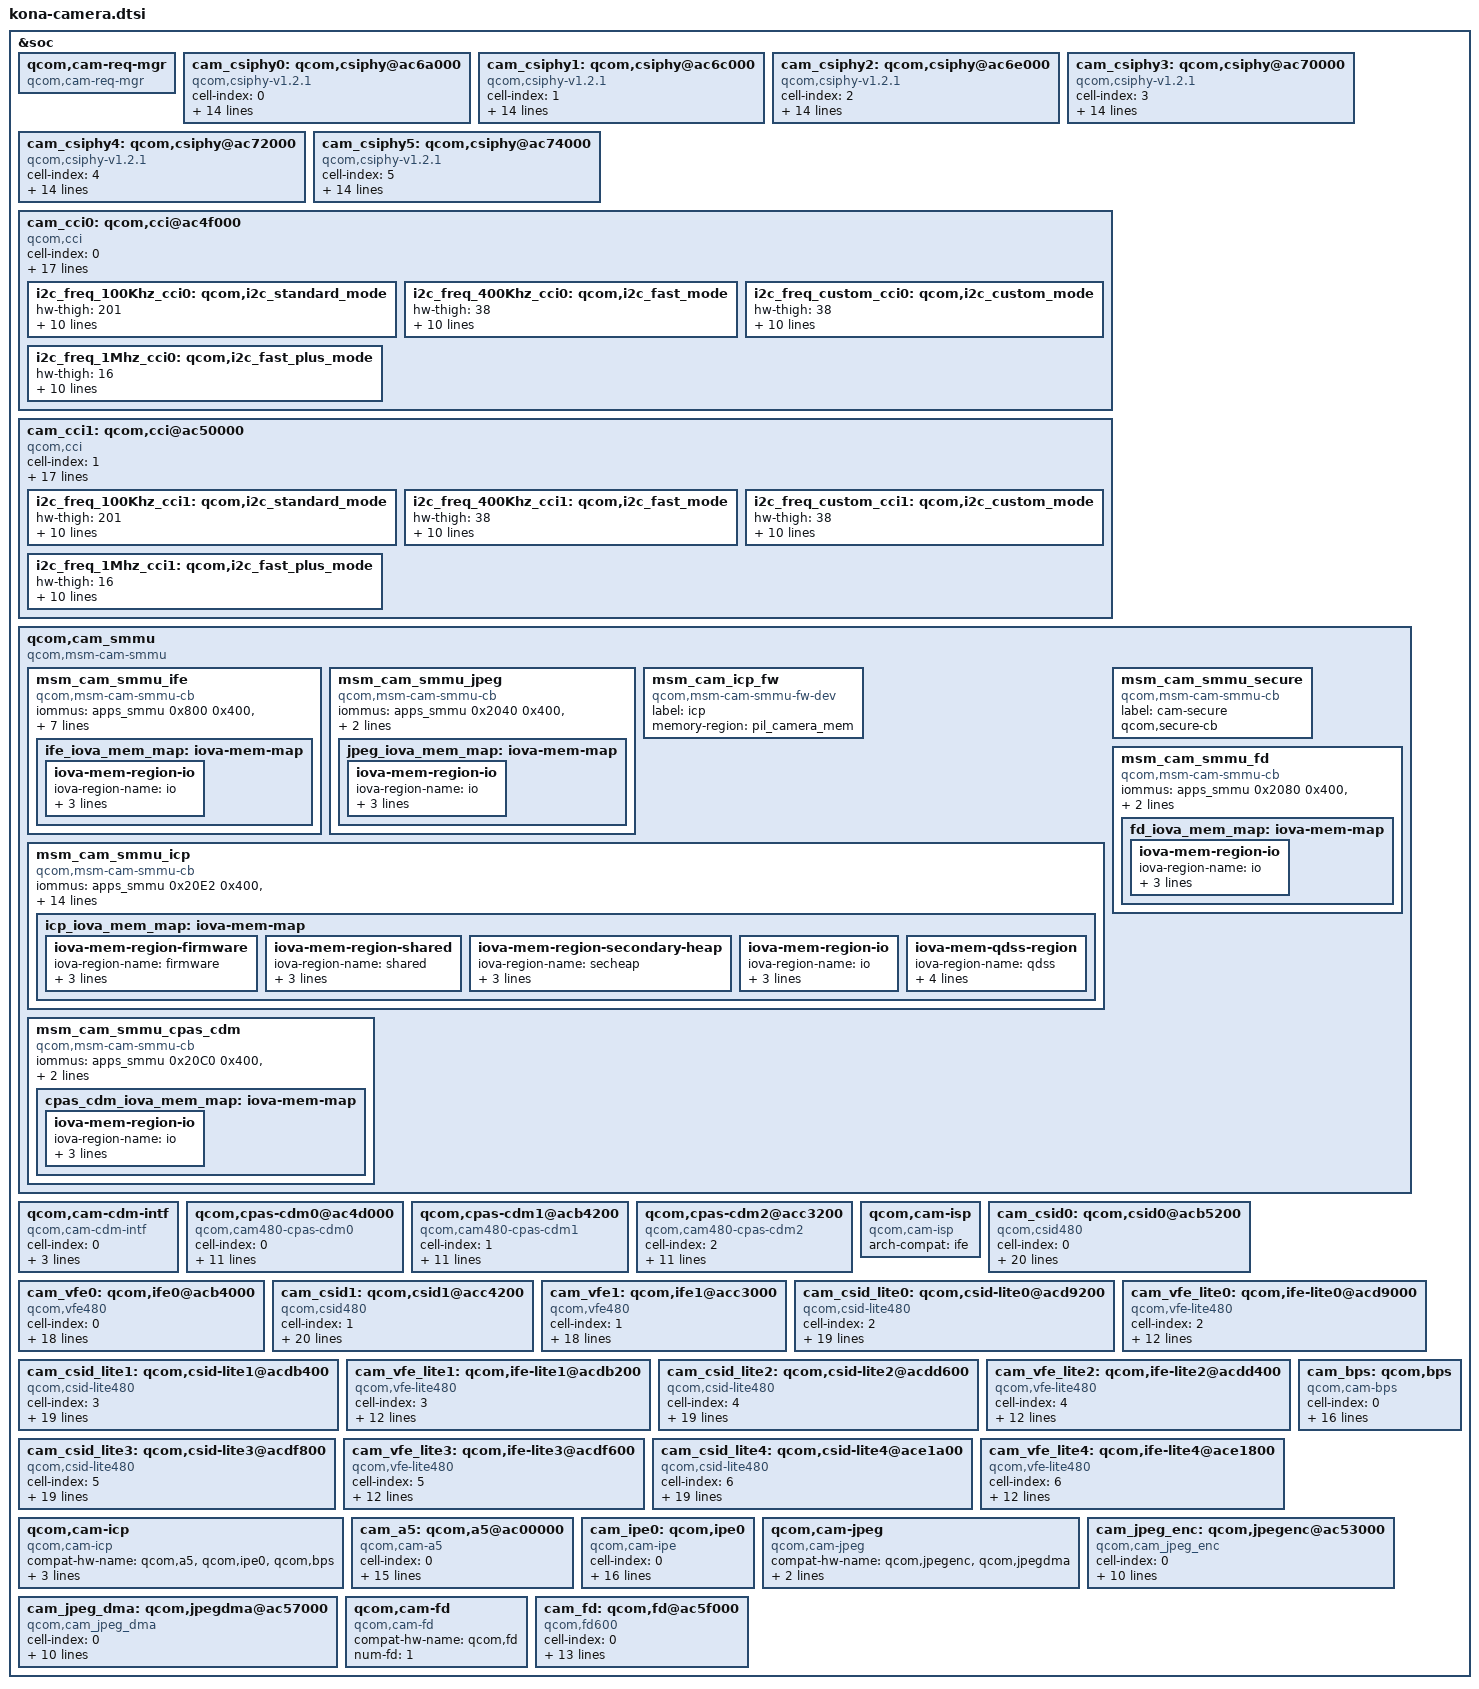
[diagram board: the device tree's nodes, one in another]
// SPDX-License-Identifier: GPL-2.0-only
/*
 * Copyright (c) 2018, The Linux Foundation. All rights reserved.
 */

&soc {
	qcom,cam-req-mgr {
		compatible = "qcom,cam-req-mgr";
		status = "ok";
	};

	cam_csiphy0: qcom,csiphy@ac6a000 {
		cell-index = <0>;
		compatible = "qcom,csiphy-v1.2.1", "qcom,csiphy";
		reg = <0x0ac6a000 0x2000>;
		reg-names = "csiphy";
		reg-cam-base = <0x6a000>;
		interrupts = <GIC_SPI 477 IRQ_TYPE_EDGE_RISING>;
		interrupt-names = "csiphy";
		gdscr-supply = <&titan_top_gdsc>;
		regulator-names = "gdscr";
		csi-vdd-voltage = <1200000>;
		mipi-csi-vdd-supply = <&pm8150_l9>;
		clocks = <&clock_camcc CAM_CC_CPHY_RX_CLK_SRC>,
			<&clock_camcc CAM_CC_CSIPHY0_CLK>,
			<&clock_camcc CAM_CC_CSI0PHYTIMER_CLK_SRC>,
			<&clock_camcc CAM_CC_CSI0PHYTIMER_CLK>;
		clock-names = "cphy_rx_clk_src",
			"csiphy0_clk",
			"csi0phytimer_clk_src",
			"csi0phytimer_clk";
		src-clock-name = "csi0phytimer_clk_src";
		clock-cntl-level = "turbo";
		clock-rates =
			<400000000 0 300000000 0>;
		status = "ok";
	};

	cam_csiphy1: qcom,csiphy@ac6c000 {
		cell-index = <1>;
		compatible = "qcom,csiphy-v1.2.1", "qcom,csiphy";
		reg = <0xac6c000 0x2000>;
		reg-names = "csiphy";
		reg-cam-base = <0x6c000>;
		interrupts = <GIC_SPI 478 IRQ_TYPE_EDGE_RISING>;
		interrupt-names = "csiphy";
		gdscr-supply = <&titan_top_gdsc>;
		regulator-names = "gdscr";
		csi-vdd-voltage = <1200000>;
		mipi-csi-vdd-supply = <&pm8150_l9>;
		clocks = <&clock_camcc CAM_CC_CPHY_RX_CLK_SRC>,
			<&clock_camcc CAM_CC_CSIPHY1_CLK>,
			<&clock_camcc CAM_CC_CSI1PHYTIMER_CLK_SRC>,
			<&clock_camcc CAM_CC_CSI1PHYTIMER_CLK>;
		clock-names = "cphy_rx_clk_src",
			"csiphy1_clk",
			"csi1phytimer_clk_src",
			"csi1phytimer_clk";
		src-clock-name = "csi1phytimer_clk_src";
		clock-cntl-level = "turbo";
		clock-rates =
			<400000000 0 300000000 0>;

		status = "ok";
	};

	cam_csiphy2: qcom,csiphy@ac6e000 {
		cell-index = <2>;
		compatible = "qcom,csiphy-v1.2.1", "qcom,csiphy";
		reg = <0xac6e000 0x2000>;
		reg-names = "csiphy";
		reg-cam-base = <0x6e000>;
		interrupts = <GIC_SPI 479 IRQ_TYPE_EDGE_RISING>;
		interrupt-names = "csiphy";
		gdscr-supply = <&titan_top_gdsc>;
		regulator-names = "gdscr";
		csi-vdd-voltage = <1200000>;
		mipi-csi-vdd-supply = <&pm8150_l9>;
		clocks = <&clock_camcc CAM_CC_CPHY_RX_CLK_SRC>,
			<&clock_camcc CAM_CC_CSIPHY2_CLK>,
			<&clock_camcc CAM_CC_CSI2PHYTIMER_CLK_SRC>,
			<&clock_camcc CAM_CC_CSI2PHYTIMER_CLK>;
		clock-names = "cphy_rx_clk_src",
			"csiphy2_clk",
			"csi2phytimer_clk_src",
			"csi2phytimer_clk";
		src-clock-name = "csi2phytimer_clk_src";
		clock-cntl-level = "turbo";
		clock-rates =
			<400000000 0 300000000 0>;
		status = "ok";
	};

	cam_csiphy3: qcom,csiphy@ac70000 {
		cell-index = <3>;
		compatible = "qcom,csiphy-v1.2.1", "qcom,csiphy";
		reg = <0xac70000 0x2000>;
		reg-names = "csiphy";
		reg-cam-base = <0x70000>;
		interrupts = <GIC_SPI 448 IRQ_TYPE_EDGE_RISING>;
		interrupt-names = "csiphy";
		gdscr-supply = <&titan_top_gdsc>;
		regulator-names = "gdscr";
		csi-vdd-voltage = <1200000>;
		mipi-csi-vdd-supply = <&pm8150_l9>;
		clocks = <&clock_camcc CAM_CC_CPHY_RX_CLK_SRC>,
			<&clock_camcc CAM_CC_CSIPHY3_CLK>,
			<&clock_camcc CAM_CC_CSI3PHYTIMER_CLK_SRC>,
			<&clock_camcc CAM_CC_CSI3PHYTIMER_CLK>;
		clock-names = "cphy_rx_clk_src",
			"csiphy3_clk",
			"csi3phytimer_clk_src",
			"csi3phytimer_clk";
		src-clock-name = "csi3phytimer_clk_src";
		clock-cntl-level = "turbo";
		clock-rates =
			<400000000 0 300000000 0>;
		status = "ok";
	};

	cam_csiphy4: qcom,csiphy@ac72000 {
		cell-index = <4>;
		compatible = "qcom,csiphy-v1.2.1", "qcom,csiphy";
		reg = <0xac72000 0x2000>;
		reg-names = "csiphy";
		reg-cam-base = <0x72000>;
		interrupts = <GIC_SPI 86 IRQ_TYPE_EDGE_RISING>;
		interrupt-names = "csiphy";
		gdscr-supply = <&titan_top_gdsc>;
		regulator-names = "gdscr";
		csi-vdd-voltage = <1200000>;
		mipi-csi-vdd-supply = <&pm8150_l9>;
		clocks = <&clock_camcc CAM_CC_CPHY_RX_CLK_SRC>,
			<&clock_camcc CAM_CC_CSIPHY4_CLK>,
			<&clock_camcc CAM_CC_CSI4PHYTIMER_CLK_SRC>,
			<&clock_camcc CAM_CC_CSI4PHYTIMER_CLK>;
		clock-names = "cphy_rx_clk_src",
			"csiphy4_clk",
			"csi4phytimer_clk_src",
			"csi4phytimer_clk";
		src-clock-name = "csi4phytimer_clk_src";
		clock-cntl-level = "turbo";
		clock-rates =
			<400000000 0 300000000 0>;
		status = "ok";
	};

	cam_csiphy5: qcom,csiphy@ac74000 {
		cell-index = <5>;
		compatible = "qcom,csiphy-v1.2.1", "qcom,csiphy";
		reg = <0xac74000 0x2000>;
		reg-names = "csiphy";
		reg-cam-base = <0x74000>;
		interrupts = <GIC_SPI 89 IRQ_TYPE_EDGE_RISING>;
		interrupt-names = "csiphy";
		gdscr-supply = <&titan_top_gdsc>;
		regulator-names = "gdscr";
		csi-vdd-voltage = <1200000>;
		mipi-csi-vdd-supply = <&pm8150_l9>;
		clocks = <&clock_camcc CAM_CC_CPHY_RX_CLK_SRC>,
			<&clock_camcc CAM_CC_CSIPHY5_CLK>,
			<&clock_camcc CAM_CC_CSI5PHYTIMER_CLK_SRC>,
			<&clock_camcc CAM_CC_CSI5PHYTIMER_CLK>;
		clock-names = "cphy_rx_clk_src",
			"csiphy5_clk",
			"csi5phytimer_clk_src",
			"csi5phytimer_clk";
		src-clock-name = "csi5phytimer_clk_src";
		clock-cntl-level = "turbo";
		clock-rates =
			<400000000 0 300000000 0>;
		status = "ok";
	};

	cam_cci0: qcom,cci@ac4f000 {
		cell-index = <0>;
		compatible = "qcom,cci";
		reg = <0xac4f000 0x1000>;
		reg-names = "cci";
		reg-cam-base = <0x4f000>;
		interrupt-names = "cci";
		interrupts = <GIC_SPI 460 IRQ_TYPE_EDGE_RISING>;
		status = "ok";
		gdscr-supply = <&titan_top_gdsc>;
		regulator-names = "gdscr";
		clocks = <&clock_camcc CAM_CC_CCI_0_CLK_SRC>,
			<&clock_camcc CAM_CC_CCI_0_CLK>;
		clock-names = "cci_0_clk_src",
			"cci_0_clk";
		src-clock-name = "cci_0_clk_src";
		clock-cntl-level = "lowsvs";
		clock-rates = <37500000 0>;
		pinctrl-names = "cam_default", "cam_suspend";
		pinctrl-0 = <&cci0_active &cci1_active>;
		pinctrl-1 = <&cci0_suspend &cci1_suspend>;
		gpios = <&tlmm 17 0>,
			<&tlmm 18 0>,
			<&tlmm 19 0>,
			<&tlmm 20 0>;
		gpio-req-tbl-num = <0 1 2 3>;
		gpio-req-tbl-flags = <1 1 1 1>;
		gpio-req-tbl-label = "CCI_I2C_DATA0",
					"CCI_I2C_CLK0",
					"CCI_I2C_DATA1",
					"CCI_I2C_CLK1";

		i2c_freq_100Khz_cci0: qcom,i2c_standard_mode {
			hw-thigh = <201>;
			hw-tlow = <174>;
			hw-tsu-sto = <204>;
			hw-tsu-sta = <231>;
			hw-thd-dat = <22>;
			hw-thd-sta = <162>;
			hw-tbuf = <227>;
			hw-scl-stretch-en = <0>;
			hw-trdhld = <6>;
			hw-tsp = <3>;
			cci-clk-src = <37500000>;
			status = "ok";
		};

		i2c_freq_400Khz_cci0: qcom,i2c_fast_mode {
			hw-thigh = <38>;
			hw-tlow = <56>;
			hw-tsu-sto = <40>;
			hw-tsu-sta = <40>;
			hw-thd-dat = <22>;
			hw-thd-sta = <35>;
			hw-tbuf = <62>;
			hw-scl-stretch-en = <0>;
			hw-trdhld = <6>;
			hw-tsp = <3>;
			cci-clk-src = <37500000>;
			status = "ok";
		};

		i2c_freq_custom_cci0: qcom,i2c_custom_mode {
			hw-thigh = <38>;
			hw-tlow = <56>;
			hw-tsu-sto = <40>;
			hw-tsu-sta = <40>;
			hw-thd-dat = <22>;
			hw-thd-sta = <35>;
			hw-tbuf = <62>;
			hw-scl-stretch-en = <1>;
			hw-trdhld = <6>;
			hw-tsp = <3>;
			cci-clk-src = <37500000>;
			status = "ok";
		};

		i2c_freq_1Mhz_cci0: qcom,i2c_fast_plus_mode {
			hw-thigh = <16>;
			hw-tlow = <22>;
			hw-tsu-sto = <17>;
			hw-tsu-sta = <18>;
			hw-thd-dat = <16>;
			hw-thd-sta = <15>;
			hw-tbuf = <24>;
			hw-scl-stretch-en = <0>;
			hw-trdhld = <3>;
			hw-tsp = <3>;
			cci-clk-src = <37500000>;
			status = "ok";
		};
	};

	cam_cci1: qcom,cci@ac50000 {
		cell-index = <1>;
		compatible = "qcom,cci";
		reg = <0xac50000 0x1000>;
		reg-names = "cci";
		reg-cam-base = <0x50000>;
		interrupt-names = "cci";
		interrupts = <GIC_SPI 271 IRQ_TYPE_EDGE_RISING>;
		status = "ok";
		gdscr-supply = <&titan_top_gdsc>;
		regulator-names = "gdscr";
		clocks = <&clock_camcc CAM_CC_CCI_1_CLK_SRC>,
			<&clock_camcc CAM_CC_CCI_1_CLK>;
		clock-names = "cci_1_clk_src",
			"cci_1_clk";
		src-clock-name = "cci_1_clk_src";
		clock-cntl-level = "lowsvs";
		clock-rates = <37500000 0>;
		pinctrl-names = "cam_default", "cam_suspend";
		pinctrl-0 = <&cci2_active &cci3_active>;
		pinctrl-1 = <&cci2_suspend &cci3_suspend>;
		gpios = <&tlmm 31 0>,
			<&tlmm 32 0>,
			<&tlmm 33 0>,
			<&tlmm 34 0>;
		gpio-req-tbl-num = <0 1 2 3>;
		gpio-req-tbl-flags = <1 1 1 1>;
		gpio-req-tbl-label = "CCI_I2C_DATA2",
					"CCI_I2C_CLK2",
					"CCI_I2C_DATA3",
					"CCI_I2C_CLK3";

		i2c_freq_100Khz_cci1: qcom,i2c_standard_mode {
			hw-thigh = <201>;
			hw-tlow = <174>;
			hw-tsu-sto = <204>;
			hw-tsu-sta = <231>;
			hw-thd-dat = <22>;
			hw-thd-sta = <162>;
			hw-tbuf = <227>;
			hw-scl-stretch-en = <0>;
			hw-trdhld = <6>;
			hw-tsp = <3>;
			cci-clk-src = <37500000>;
			status = "ok";
		};

		i2c_freq_400Khz_cci1: qcom,i2c_fast_mode {
			hw-thigh = <38>;
			hw-tlow = <56>;
			hw-tsu-sto = <40>;
			hw-tsu-sta = <40>;
			hw-thd-dat = <22>;
			hw-thd-sta = <35>;
			hw-tbuf = <62>;
			hw-scl-stretch-en = <0>;
			hw-trdhld = <6>;
			hw-tsp = <3>;
			cci-clk-src = <37500000>;
			status = "ok";
		};

		i2c_freq_custom_cci1: qcom,i2c_custom_mode {
			hw-thigh = <38>;
			hw-tlow = <56>;
			hw-tsu-sto = <40>;
			hw-tsu-sta = <40>;
			hw-thd-dat = <22>;
			hw-thd-sta = <35>;
			hw-tbuf = <62>;
			hw-scl-stretch-en = <1>;
			hw-trdhld = <6>;
			hw-tsp = <3>;
			cci-clk-src = <37500000>;
			status = "ok";
		};

		i2c_freq_1Mhz_cci1: qcom,i2c_fast_plus_mode {
			hw-thigh = <16>;
			hw-tlow = <22>;
			hw-tsu-sto = <17>;
			hw-tsu-sta = <18>;
			hw-thd-dat = <16>;
			hw-thd-sta = <15>;
			hw-tbuf = <24>;
			hw-scl-stretch-en = <0>;
			hw-trdhld = <3>;
			hw-tsp = <3>;
			cci-clk-src = <37500000>;
			status = "ok";
		};
	};

	qcom,cam_smmu {
		compatible = "qcom,msm-cam-smmu";
		status = "ok";

		msm_cam_smmu_ife {
			compatible = "qcom,msm-cam-smmu-cb";
			iommus = <&apps_smmu 0x800 0x400>,
				<&apps_smmu 0x801 0x400>,
				<&apps_smmu 0x840 0x400>,
				<&apps_smmu 0x841 0x400>,
				<&apps_smmu 0xC00 0x400>,
				<&apps_smmu 0xC01 0x400>,
				<&apps_smmu 0xC40 0x400>,
				<&apps_smmu 0xC41 0x400>;
			label = "ife";
			ife_iova_mem_map: iova-mem-map {
				/* IO region is approximately 3.4 GB */
				iova-mem-region-io {
					iova-region-name = "io";
					iova-region-start = <0x7400000>;
					iova-region-len = <0xd8c00000>;
					iova-region-id = <0x3>;
					status = "ok";
				};
			};
		};

		msm_cam_smmu_jpeg {
			compatible = "qcom,msm-cam-smmu-cb";
			iommus = <&apps_smmu 0x2040 0x400>,
				<&apps_smmu 0x2440 0x400>;
			label = "jpeg";
			jpeg_iova_mem_map: iova-mem-map {
				/* IO region is approximately 3.4 GB */
				iova-mem-region-io {
					iova-region-name = "io";
					iova-region-start = <0x7400000>;
					iova-region-len = <0xd8c00000>;
					iova-region-id = <0x3>;
					status = "ok";
				};
			};
		};

		msm_cam_icp_fw {
			compatible = "qcom,msm-cam-smmu-fw-dev";
			label="icp";
			memory-region = <&pil_camera_mem>;
		};

		msm_cam_smmu_icp {
			compatible = "qcom,msm-cam-smmu-cb";
			iommus = <&apps_smmu 0x20E2 0x400>,
				<&apps_smmu 0x24E2 0x400>,
				<&apps_smmu 0x2000 0x400>,
				<&apps_smmu 0x2001 0x400>,
				<&apps_smmu 0x2400 0x400>,
				<&apps_smmu 0x2401 0x400>,
				<&apps_smmu 0x2060 0x400>,
				<&apps_smmu 0x2061 0x400>,
				<&apps_smmu 0x2460 0x400>,
				<&apps_smmu 0x2461 0x400>,
				<&apps_smmu 0x2020 0x400>,
				<&apps_smmu 0x2021 0x400>,
				<&apps_smmu 0x2420 0x400>,
				<&apps_smmu 0x2421 0x400>;
			label = "icp";
			icp_iova_mem_map: iova-mem-map {
				iova-mem-region-firmware {
					/* Firmware region is 5MB */
					iova-region-name = "firmware";
					iova-region-start = <0x0>;
					iova-region-len = <0x500000>;
					iova-region-id = <0x0>;
					status = "ok";
				};

				iova-mem-region-shared {
					/* Shared region is 100MB long */
					iova-region-name = "shared";
					iova-region-start = <0x7400000>;
					iova-region-len = <0x6400000>;
					iova-region-id = <0x1>;
					status = "ok";
				};

				iova-mem-region-secondary-heap {
					/* Secondary heap region is 1MB long */
					iova-region-name = "secheap";
					iova-region-start = <0xd800000>;
					iova-region-len = <0x100000>;
					iova-region-id = <0x4>;
					status = "ok";
				};

				iova-mem-region-io {
					/* IO region is approximately 3 GB */
					iova-region-name = "io";
					iova-region-start = <0xda00000>;
					iova-region-len = <0xace00000>;
					iova-region-id = <0x3>;
					status = "ok";
				};

				iova-mem-qdss-region {
					/* QDSS region is appropriate 1MB */
					iova-region-name = "qdss";
					iova-region-start = <0xd900000>;
					iova-region-len = <0x100000>;
					iova-region-id = <0x5>;
					qdss-phy-addr = <0x16790000>;
					status = "ok";
				};
			};
		};

		msm_cam_smmu_cpas_cdm {
			compatible = "qcom,msm-cam-smmu-cb";
			iommus = <&apps_smmu 0x20C0 0x400>,
				<&apps_smmu 0x24C0 0x400>;
			label = "cpas-cdm0";
			cpas_cdm_iova_mem_map: iova-mem-map {
				iova-mem-region-io {
					/* IO region is approximately 3.4 GB */
					iova-region-name = "io";
					iova-region-start = <0x7400000>;
					iova-region-len = <0xd8c00000>;
					iova-region-id = <0x3>;
					status = "ok";
				};
			};
		};

		msm_cam_smmu_secure {
			compatible = "qcom,msm-cam-smmu-cb";
			label = "cam-secure";
			qcom,secure-cb;
		};

		msm_cam_smmu_fd {
			compatible = "qcom,msm-cam-smmu-cb";
			iommus = <&apps_smmu 0x2080 0x400>,
				<&apps_smmu 0x2480 0x400>;
			label = "fd";
			fd_iova_mem_map: iova-mem-map {
				iova-mem-region-io {
					/* IO region is approximately 3.4 GB */
					iova-region-name = "io";
					iova-region-start = <0x7400000>;
					iova-region-len = <0xd8c00000>;
					iova-region-id = <0x3>;
					status = "ok";
				};
			};
		};
	};

	qcom,cam-cdm-intf {
		compatible = "qcom,cam-cdm-intf";
		cell-index = <0>;
		label = "cam-cdm-intf";
		num-hw-cdm = <3>;
		cdm-client-names = "vfe",
			"jpegdma",
			"jpegenc",
			"fd";
		status = "ok";
	};

	qcom,cpas-cdm0@ac4d000 {
		cell-index = <0>;
		compatible = "qcom,cam480-cpas-cdm0";
		label = "cpas-cdm";
		reg = <0xac4d000 0x1000>;
		reg-names = "cpas-cdm";
		reg-cam-base = <0x4d000>;
		interrupts = <GIC_SPI 461 IRQ_TYPE_EDGE_RISING>;
		interrupt-names = "cpas-cdm";
		regulator-names = "camss";
		camss-supply = <&titan_top_gdsc>;
		clock-names = "cam_cc_cpas_slow_ahb_clk",
			"cam_cc_cpas_ahb_clk";
		clocks = <&clock_camcc CAM_CC_SLOW_AHB_CLK_SRC>,
			<&clock_camcc CAM_CC_CPAS_AHB_CLK>;
		clock-rates = <0 0>;
		clock-cntl-level = "svs";
		cdm-client-names = "ife2", "ife3", "ife4", "ife5", "ife6";
		status = "ok";
	};

	qcom,cpas-cdm1@acb4200 {
		cell-index = <1>;
		compatible = "qcom,cam480-cpas-cdm1";
		label = "cpas-cdm";
		reg = <0xacb4200 0x1000>;
		reg-names = "cpas-cdm";
		reg-cam-base = <0xb4200>;
		interrupts = <GIC_SPI 456 IRQ_TYPE_EDGE_RISING>;
		interrupt-names = "cpas-cdm";
		regulator-names = "camss";
		camss-supply = <&titan_top_gdsc>;
		clock-names = "cam_cc_cpas_slow_ahb_clk",
			"cam_cc_cpas_ahb_clk";
		clocks = <&clock_camcc CAM_CC_SLOW_AHB_CLK_SRC>,
			<&clock_camcc CAM_CC_CPAS_AHB_CLK>;
		clock-rates = <0 0>;
		clock-cntl-level = "svs";
		cdm-client-names = "ife0";
		status = "ok";
	};

	qcom,cpas-cdm2@acc3200 {
		cell-index = <2>;
		compatible = "qcom,cam480-cpas-cdm2";
		label = "cpas-cdm";
		reg = <0xacc3200 0x1000>;
		reg-names = "cpas-cdm";
		reg-cam-base = <0xc3200>;
		interrupts = <GIC_SPI 287 IRQ_TYPE_EDGE_RISING>;
		interrupt-names = "cpas-cdm";
		regulator-names = "camss";
		camss-supply = <&titan_top_gdsc>;
		clock-names = "cam_cc_cpas_slow_ahb_clk",
			"cam_cc_cpas_ahb_clk";
		clocks = <&clock_camcc CAM_CC_SLOW_AHB_CLK_SRC>,
			<&clock_camcc CAM_CC_CPAS_AHB_CLK>;
		clock-rates = <0 0>;
		clock-cntl-level = "svs";
		cdm-client-names = "ife1";
		status = "ok";
	};

	qcom,cam-isp {
		compatible = "qcom,cam-isp";
		arch-compat = "ife";
		status = "ok";
	};

	cam_csid0: qcom,csid0@acb5200 {
		cell-index = <0>;
		compatible = "qcom,csid480";
		reg-names = "csid";
		reg = <0xacb5200 0x1000>;
		reg-cam-base = <0xb5200>;
		interrupt-names = "csid";
		interrupts = <GIC_SPI 464 IRQ_TYPE_EDGE_RISING>;
		regulator-names = "camss", "ife0";
		camss-supply = <&titan_top_gdsc>;
		ife0-supply = <&ife_0_gdsc>;
		clock-names =
			"ife_csid_clk_src",
			"ife_csid_clk",
			"cphy_rx_clk_src",
			"ife_cphy_rx_clk",
			"ife_clk_src",
			"ife_clk",
			"ife_axi_clk";
		clocks =
			<&clock_camcc CAM_CC_IFE_0_CSID_CLK_SRC>,
			<&clock_camcc CAM_CC_IFE_0_CSID_CLK>,
			<&clock_camcc CAM_CC_CPHY_RX_CLK_SRC>,
			<&clock_camcc CAM_CC_IFE_0_CPHY_RX_CLK>,
			<&clock_camcc CAM_CC_IFE_0_CLK_SRC>,
			<&clock_camcc CAM_CC_IFE_0_CLK>,
			<&clock_camcc CAM_CC_IFE_0_AXI_CLK>;
		clock-rates =
			<400000000 0 0 0 350000000 0 0>,
			<400000000 0 0 0 475000000 0 0>,
			<400000000 0 0 0 576000000 0 0>,
			<400000000 0 0 0 720000000 0 0>;
		clock-cntl-level = "lowsvs", "svs", "svs_l1", "turbo";
		src-clock-name = "ife_csid_clk_src";
		clock-control-debugfs = "true";
		status = "ok";
	};

	cam_vfe0: qcom,ife0@acb4000 {
		cell-index = <0>;
		compatible = "qcom,vfe480";
		reg-names = "ife", "cam_camnoc";
		reg = <0xacb4000 0xd000>,
			<0xac42000 0x8000>;
		reg-cam-base = <0xb4000 0x42000>;
		interrupt-names = "ife";
		interrupts = <GIC_SPI 465 IRQ_TYPE_EDGE_RISING>;
		regulator-names = "camss", "ife0";
		camss-supply = <&titan_top_gdsc>;
		ife0-supply = <&ife_0_gdsc>;
		clock-names =
			"ife_clk_src",
			"ife_clk",
			"ife_axi_clk";
		clocks =
			<&clock_camcc CAM_CC_IFE_0_CLK_SRC>,
			<&clock_camcc CAM_CC_IFE_0_CLK>,
			<&clock_camcc CAM_CC_IFE_0_AXI_CLK>;
		clock-rates =
			<350000000 0 0>,
			<475000000 0 0>,
			<576000000 0 0>,
			<720000000 0 0>;
		clock-cntl-level = "lowsvs", "svs", "svs_l1", "turbo";
		src-clock-name = "ife_clk_src";
		clock-control-debugfs = "true";
		clock-names-option =  "ife_dsp_clk";
		clocks-option = <&clock_camcc CAM_CC_IFE_0_DSP_CLK>;
		clock-rates-option = <720000000>;
		status = "ok";
	};

	cam_csid1: qcom,csid1@acc4200 {
		cell-index = <1>;
		compatible = "qcom,csid480";
		reg-names = "csid";
		reg = <0xacc4200 0x1000>;
		reg-cam-base = <0xc4200>;
		interrupt-names = "csid";
		interrupts = <GIC_SPI 466 IRQ_TYPE_EDGE_RISING>;
		regulator-names = "camss", "ife1";
		camss-supply = <&titan_top_gdsc>;
		ife1-supply = <&ife_1_gdsc>;
		clock-names =
			"ife_csid_clk_src",
			"ife_csid_clk",
			"cphy_rx_clk_src",
			"ife_cphy_rx_clk",
			"ife_clk_src",
			"ife_clk",
			"ife_axi_clk";
		clocks =
			<&clock_camcc CAM_CC_IFE_1_CSID_CLK_SRC>,
			<&clock_camcc CAM_CC_IFE_1_CSID_CLK>,
			<&clock_camcc CAM_CC_CPHY_RX_CLK_SRC>,
			<&clock_camcc CAM_CC_IFE_1_CPHY_RX_CLK>,
			<&clock_camcc CAM_CC_IFE_1_CLK_SRC>,
			<&clock_camcc CAM_CC_IFE_1_CLK>,
			<&clock_camcc CAM_CC_IFE_1_AXI_CLK>;
		clock-rates =
			<400000000 0 0 0 350000000 0 0>,
			<400000000 0 0 0 475000000 0 0>,
			<400000000 0 0 0 576000000 0 0>,
			<400000000 0 0 0 720000000 0 0>;
		clock-cntl-level = "lowsvs", "svs", "svs_l1", "turbo";
		src-clock-name = "ife_csid_clk_src";
		clock-control-debugfs = "true";
		status = "ok";
	};

	cam_vfe1: qcom,ife1@acc3000 {
		cell-index = <1>;
		compatible = "qcom,vfe480";
		reg-names = "ife", "cam_camnoc";
		reg = <0xacc3000 0xd000>,
			<0xac42000 0x8000>;
		reg-cam-base = <0xc3000 0x42000>;
		interrupt-names = "ife";
		interrupts = <GIC_SPI 467 IRQ_TYPE_EDGE_RISING>;
		regulator-names = "camss", "ife1";
		camss-supply = <&titan_top_gdsc>;
		ife1-supply = <&ife_1_gdsc>;
		clock-names =
			"ife_clk_src",
			"ife_clk",
			"ife_axi_clk";
		clocks =
			<&clock_camcc CAM_CC_IFE_1_CLK_SRC>,
			<&clock_camcc CAM_CC_IFE_1_CLK>,
			<&clock_camcc CAM_CC_IFE_1_AXI_CLK>;
		clock-rates =
			<350000000 0 0>,
			<475000000 0 0>,
			<576000000 0 0>,
			<720000000 0 0>;
		clock-cntl-level = "lowsvs", "svs", "svs_l1", "turbo";
		src-clock-name = "ife_clk_src";
		clock-control-debugfs = "true";
		clock-names-option =  "ife_dsp_clk";
		clocks-option = <&clock_camcc CAM_CC_IFE_1_DSP_CLK>;
		clock-rates-option = <720000000>;
		status = "ok";
	};

	cam_csid_lite0: qcom,csid-lite0@acd9200 {
		cell-index = <2>;
		compatible = "qcom,csid-lite480";
		reg-names = "csid-lite";
		reg = <0xacd9200 0x1000>;
		reg-cam-base = <0xd9200>;
		interrupt-names = "csid-lite";
		interrupts = <GIC_SPI 468 IRQ_TYPE_EDGE_RISING>;
		regulator-names = "camss";
		camss-supply = <&titan_top_gdsc>;
		clock-names =
			"ife_csid_clk_src",
			"ife_csid_clk",
			"cphy_rx_clk_src",
			"ife_cphy_rx_clk",
			"ife_clk_src",
			"ife_clk";
		clocks =
			<&clock_camcc CAM_CC_IFE_LITE_CSID_CLK_SRC>,
			<&clock_camcc CAM_CC_IFE_LITE_CSID_CLK>,
			<&clock_camcc CAM_CC_CPHY_RX_CLK_SRC>,
			<&clock_camcc CAM_CC_IFE_LITE_CPHY_RX_CLK>,
			<&clock_camcc CAM_CC_IFE_LITE_CLK_SRC>,
			<&clock_camcc CAM_CC_IFE_LITE_CLK>;
		clock-rates =
			<400000000 0 0 0 400000000 0>,
			<400000000 0 0 0 480000000 0>,
			<400000000 0 0 0 480000000 0>,
			<400000000 0 0 0 480000000 0>;
		clock-cntl-level = "lowsvs", "svs", "svs_l1", "turbo";
		src-clock-name = "ife_csid_clk_src";
		clock-control-debugfs = "true";
		status = "ok";
	};

	cam_vfe_lite0: qcom,ife-lite0@acd9000 {
		cell-index = <2>;
		compatible = "qcom,vfe-lite480";
		reg-names = "ife-lite";
		reg = <0xacd9000 0x2200>;
		reg-cam-base = <0xd9000>;
		interrupt-names = "ife-lite";
		interrupts = <GIC_SPI 469 IRQ_TYPE_EDGE_RISING>;
		regulator-names = "camss";
		camss-supply = <&titan_top_gdsc>;
		clock-names =
			"ife_clk_src",
			"ife_clk";
		clocks =
			<&clock_camcc CAM_CC_IFE_LITE_CLK_SRC>,
			<&clock_camcc CAM_CC_IFE_LITE_CLK>;
		clock-rates =
			<400000000 0>,
			<480000000 0>,
			<480000000 0>,
			<480000000 0>;
		clock-cntl-level = "lowsvs", "svs", "svs_l1", "turbo";
		src-clock-name = "ife_clk_src";
		clock-control-debugfs = "true";
		status = "ok";
	};

	cam_csid_lite1: qcom,csid-lite1@acdb400 {
		cell-index = <3>;
		compatible = "qcom,csid-lite480";
		reg-names = "csid-lite";
		reg = <0xacdb400 0x1000>;
		reg-cam-base = <0xdb400>;
		interrupt-names = "csid-lite";
		interrupts = <GIC_SPI 359 IRQ_TYPE_EDGE_RISING>;
		regulator-names = "camss";
		camss-supply = <&titan_top_gdsc>;
		clock-names =
			"ife_csid_clk_src",
			"ife_csid_clk",
			"cphy_rx_clk_src",
			"ife_cphy_rx_clk",
			"ife_clk_src",
			"ife_clk";
		clocks =
			<&clock_camcc CAM_CC_IFE_LITE_CSID_CLK_SRC>,
			<&clock_camcc CAM_CC_IFE_LITE_CSID_CLK>,
			<&clock_camcc CAM_CC_CPHY_RX_CLK_SRC>,
			<&clock_camcc CAM_CC_IFE_LITE_CPHY_RX_CLK>,
			<&clock_camcc CAM_CC_IFE_LITE_CLK_SRC>,
			<&clock_camcc CAM_CC_IFE_LITE_CLK>;
		clock-rates =
			<400000000 0 0 0 400000000 0>,
			<400000000 0 0 0 480000000 0>,
			<400000000 0 0 0 480000000 0>,
			<400000000 0 0 0 480000000 0>;
		clock-cntl-level = "lowsvs", "svs", "svs_l1", "turbo";
		src-clock-name = "ife_csid_clk_src";
		clock-control-debugfs = "true";
		status = "ok";
	};

	cam_vfe_lite1: qcom,ife-lite1@acdb200 {
		cell-index = <3>;
		compatible = "qcom,vfe-lite480";
		reg-names = "ife-lite";
		reg = <0xacdb200 0x2200>;
		reg-cam-base = <0xdb200>;
		interrupt-names = "ife-lite";
		interrupts = <GIC_SPI 360 IRQ_TYPE_EDGE_RISING>;
		regulator-names = "camss";
		camss-supply = <&titan_top_gdsc>;
		clock-names =
			"ife_clk_src",
			"ife_clk";
		clocks =
			<&clock_camcc CAM_CC_IFE_LITE_CLK_SRC>,
			<&clock_camcc CAM_CC_IFE_LITE_CLK>;
		clock-rates =
			<400000000 0>,
			<480000000 0>,
			<480000000 0>,
			<480000000 0>;
		clock-cntl-level = "lowsvs", "svs", "svs_l1", "turbo";
		src-clock-name = "ife_clk_src";
		clock-control-debugfs = "true";
		status = "ok";
	};

	cam_csid_lite2: qcom,csid-lite2@acdd600 {
		cell-index = <4>;
		compatible = "qcom,csid-lite480";
		reg-names = "csid-lite";
		reg = <0xacdd600 0x1000>;
		reg-cam-base = <0xdd600>;
		interrupt-names = "csid-lite";
		interrupts = <GIC_SPI 449 IRQ_TYPE_EDGE_RISING>;
		regulator-names = "camss";
		camss-supply = <&titan_top_gdsc>;
		clock-names =
			"ife_csid_clk_src",
			"ife_csid_clk",
			"cphy_rx_clk_src",
			"ife_cphy_rx_clk",
			"ife_clk_src",
			"ife_clk";
		clocks =
			<&clock_camcc CAM_CC_IFE_LITE_CSID_CLK_SRC>,
			<&clock_camcc CAM_CC_IFE_LITE_CSID_CLK>,
			<&clock_camcc CAM_CC_CPHY_RX_CLK_SRC>,
			<&clock_camcc CAM_CC_IFE_LITE_CPHY_RX_CLK>,
			<&clock_camcc CAM_CC_IFE_LITE_CLK_SRC>,
			<&clock_camcc CAM_CC_IFE_LITE_CLK>;
		clock-rates =
			<400000000 0 0 0 400000000 0>,
			<400000000 0 0 0 480000000 0>,
			<400000000 0 0 0 480000000 0>,
			<400000000 0 0 0 480000000 0>;
		clock-cntl-level = "lowsvs", "svs", "svs_l1", "turbo";
		src-clock-name = "ife_csid_clk_src";
		clock-control-debugfs = "true";
		status = "ok";
	};

	cam_vfe_lite2: qcom,ife-lite2@acdd400 {
		cell-index = <4>;
		compatible = "qcom,vfe-lite480";
		reg-names = "ife-lite";
		reg = <0xacdd400 0x2200>;
		reg-cam-base = <0xdd400>;
		interrupt-names = "ife-lite";
		interrupts = <GIC_SPI 266 IRQ_TYPE_EDGE_RISING>;
		regulator-names = "camss";
		camss-supply = <&titan_top_gdsc>;
		clock-names =
			"ife_clk_src",
			"ife_clk";
		clocks =
			<&clock_camcc CAM_CC_IFE_LITE_CLK_SRC>,
			<&clock_camcc CAM_CC_IFE_LITE_CLK>;
		clock-rates =
			<400000000 0>,
			<480000000 0>,
			<480000000 0>,
			<480000000 0>;
		clock-cntl-level = "lowsvs", "svs", "svs_l1", "turbo";
		src-clock-name = "ife_clk_src";
		clock-control-debugfs = "true";
		status = "ok";
	};

	cam_csid_lite3: qcom,csid-lite3@acdf800 {
		cell-index = <5>;
		compatible = "qcom,csid-lite480";
		reg-names = "csid-lite";
		reg = <0xacdf800 0x1000>;
		reg-cam-base = <0xdf800>;
		interrupt-names = "csid-lite";
		interrupts = <GIC_SPI 451 IRQ_TYPE_EDGE_RISING>;
		regulator-names = "camss";
		camss-supply = <&titan_top_gdsc>;
		clock-names =
			"ife_csid_clk_src",
			"ife_csid_clk",
			"cphy_rx_clk_src",
			"ife_cphy_rx_clk",
			"ife_clk_src",
			"ife_clk";
		clocks =
			<&clock_camcc CAM_CC_IFE_LITE_CSID_CLK_SRC>,
			<&clock_camcc CAM_CC_IFE_LITE_CSID_CLK>,
			<&clock_camcc CAM_CC_CPHY_RX_CLK_SRC>,
			<&clock_camcc CAM_CC_IFE_LITE_CPHY_RX_CLK>,
			<&clock_camcc CAM_CC_IFE_LITE_CLK_SRC>,
			<&clock_camcc CAM_CC_IFE_LITE_CLK>;
		clock-rates =
			<400000000 0 0 0 400000000 0>,
			<400000000 0 0 0 480000000 0>,
			<400000000 0 0 0 480000000 0>,
			<400000000 0 0 0 480000000 0>;
		clock-cntl-level = "lowsvs", "svs", "svs_l1", "turbo";
		src-clock-name = "ife_csid_clk_src";
		clock-control-debugfs = "true";
		status = "ok";
	};

	cam_vfe_lite3: qcom,ife-lite3@acdf600 {
		cell-index = <5>;
		compatible = "qcom,vfe-lite480";
		reg-names = "ife-lite";
		reg = <0xacdf600 0x2200>;
		reg-cam-base = <0xdf600>;
		interrupt-names = "ife-lite";
		interrupts = <GIC_SPI 450 IRQ_TYPE_EDGE_RISING>;
		regulator-names = "camss";
		camss-supply = <&titan_top_gdsc>;
		clock-names =
			"ife_clk_src",
			"ife_clk";
		clocks =
			<&clock_camcc CAM_CC_IFE_LITE_CLK_SRC>,
			<&clock_camcc CAM_CC_IFE_LITE_CLK>;
		clock-rates =
			<400000000 0>,
			<480000000 0>,
			<480000000 0>,
			<480000000 0>;
		clock-cntl-level = "lowsvs", "svs", "svs_l1", "turbo";
		src-clock-name = "ife_clk_src";
		clock-control-debugfs = "true";
		status = "ok";
	};

	cam_csid_lite4: qcom,csid-lite4@ace1a00 {
		cell-index = <6>;
		compatible = "qcom,csid-lite480";
		reg-names = "csid-lite";
		reg = <0xace1a00 0x1000>;
		reg-cam-base = <0xe1a00>;
		interrupt-names = "csid-lite";
		interrupts = <GIC_SPI 453 IRQ_TYPE_EDGE_RISING>;
		regulator-names = "camss";
		camss-supply = <&titan_top_gdsc>;
		clock-names =
			"ife_csid_clk_src",
			"ife_csid_clk",
			"cphy_rx_clk_src",
			"ife_cphy_rx_clk",
			"ife_clk_src",
			"ife_clk";
		clocks =
			<&clock_camcc CAM_CC_IFE_LITE_CSID_CLK_SRC>,
			<&clock_camcc CAM_CC_IFE_LITE_CSID_CLK>,
			<&clock_camcc CAM_CC_CPHY_RX_CLK_SRC>,
			<&clock_camcc CAM_CC_IFE_LITE_CPHY_RX_CLK>,
			<&clock_camcc CAM_CC_IFE_LITE_CLK_SRC>,
			<&clock_camcc CAM_CC_IFE_LITE_CLK>;
		clock-rates =
			<400000000 0 0 0 400000000 0>,
			<400000000 0 0 0 480000000 0>,
			<400000000 0 0 0 480000000 0>,
			<400000000 0 0 0 480000000 0>;
		clock-cntl-level = "lowsvs", "svs", "svs_l1", "turbo";
		src-clock-name = "ife_csid_clk_src";
		clock-control-debugfs = "true";
		status = "ok";
	};

	cam_vfe_lite4: qcom,ife-lite4@ace1800 {
		cell-index = <6>;
		compatible = "qcom,vfe-lite480";
		reg-names = "ife-lite";
		reg = <0xace1800 0x2200>;
		reg-cam-base = <0xe1800>;
		interrupt-names = "ife-lite";
		interrupts = <GIC_SPI 452 IRQ_TYPE_EDGE_RISING>;
		regulator-names = "camss";
		camss-supply = <&titan_top_gdsc>;
		clock-names =
			"ife_clk_src",
			"ife_clk";
		clocks =
			<&clock_camcc CAM_CC_IFE_LITE_CLK_SRC>,
			<&clock_camcc CAM_CC_IFE_LITE_CLK>;
		clock-rates =
			<400000000 0>,
			<480000000 0>,
			<480000000 0>,
			<480000000 0>;
		clock-cntl-level = "lowsvs", "svs", "svs_l1", "turbo";
		src-clock-name = "ife_clk_src";
		clock-control-debugfs = "true";
		status = "ok";
	};

	qcom,cam-icp {
		compatible = "qcom,cam-icp";
		compat-hw-name = "qcom,a5",
			"qcom,ipe0",
			"qcom,bps";
		num-a5 = <1>;
		num-ipe = <1>;
		num-bps = <1>;
		status = "ok";
	};

	cam_a5: qcom,a5@ac00000 {
		cell-index = <0>;
		compatible = "qcom,cam-a5";
		reg = <0xac00000 0x6000>,
			<0xac10000 0x8000>,
			<0xac18000 0x3000>;
		reg-names = "a5_qgic", "a5_sierra", "a5_csr";
		reg-cam-base = <0x00000 0x10000 0x18000>;
		interrupts = <GIC_SPI 463 IRQ_TYPE_EDGE_RISING>;
		interrupt-names = "a5";
		regulator-names = "camss-vdd";
		camss-vdd-supply = <&titan_top_gdsc>;
		clock-names =
			"soc_fast_ahb",
			"icp_ahb_clk",
			"icp_clk_src",
			"icp_clk";
		clocks =
			<&clock_camcc CAM_CC_FAST_AHB_CLK_SRC>,
			<&clock_camcc CAM_CC_ICP_AHB_CLK>,
			<&clock_camcc CAM_CC_ICP_CLK_SRC>,
			<&clock_camcc CAM_CC_ICP_CLK>;

		clock-rates =
			<200000000 0 480000000 0>,
			<400000000 0 600000000 0>;
		clock-cntl-level = "svs", "turbo";
		fw_name = "CAMERA_ICP.elf";
		ubwc-cfg = <0x7B 0x1EF>;
		status = "ok";
	};

	cam_ipe0: qcom,ipe0 {
		cell-index = <0>;
		compatible = "qcom,cam-ipe";
		reg = <0xac9a000 0xc000>;
		reg-names = "ipe0_top";
		reg-cam-base = <0x9a000>;
		regulator-names = "ipe0-vdd";
		ipe0-vdd-supply = <&ipe_0_gdsc>;
		clock-names =
			"ipe_0_ahb_clk",
			"ipe_0_areg_clk",
			"ipe_0_axi_clk",
			"ipe_0_clk_src",
			"ipe_0_clk";
		src-clock-name = "ipe_0_clk_src";
		clock-control-debugfs = "true";
		clocks =
			<&clock_camcc CAM_CC_IPE_0_AHB_CLK>,
			<&clock_camcc CAM_CC_IPE_0_AREG_CLK>,
			<&clock_camcc CAM_CC_IPE_0_AXI_CLK>,
			<&clock_camcc CAM_CC_IPE_0_CLK_SRC>,
			<&clock_camcc CAM_CC_IPE_0_CLK>;

		clock-rates =
			<0 0 0 300000000 0>,
			<0 0 0 475000000 0>,
			<0 0 0 525000000 0>,
			<0 0 0 700000000 0>,
			<0 0 0 700000000 0>;
		clock-cntl-level = "lowsvs", "svs", "svs_l1",
				"nominal", "turbo";
		status = "ok";
	};

	cam_bps: qcom,bps {
		cell-index = <0>;
		compatible = "qcom,cam-bps";
		reg = <0xac7a000 0x8000>;
		reg-names = "bps_top";
		reg-cam-base = <0x7a000>;
		regulator-names = "bps-vdd";
		bps-vdd-supply = <&bps_gdsc>;
		clock-names =
			"bps_ahb_clk",
			"bps_areg_clk",
			"bps_axi_clk",
			"bps_clk_src",
			"bps_clk";
		src-clock-name = "bps_clk_src";
		clock-control-debugfs = "true";
		clocks =
			<&clock_camcc CAM_CC_BPS_AHB_CLK>,
			<&clock_camcc CAM_CC_BPS_AREG_CLK>,
			<&clock_camcc CAM_CC_BPS_AXI_CLK>,
			<&clock_camcc CAM_CC_BPS_CLK_SRC>,
			<&clock_camcc CAM_CC_BPS_CLK>;

		clock-rates =
			<0 0 0 200000000 0>,
			<0 0 0 400000000 0>,
			<0 0 0 480000000 0>,
			<0 0 0 600000000 0>,
			<0 0 0 600000000 0>;
		clock-cntl-level = "lowsvs", "svs", "svs_l1",
				"nominal", "turbo";
		status = "ok";
	};

	qcom,cam-jpeg {
		compatible = "qcom,cam-jpeg";
		compat-hw-name = "qcom,jpegenc",
			"qcom,jpegdma";
		num-jpeg-enc = <1>;
		num-jpeg-dma = <1>;
		status = "ok";
	};

	cam_jpeg_enc: qcom,jpegenc@ac53000 {
		cell-index = <0>;
		compatible = "qcom,cam_jpeg_enc";
		reg-names = "jpege_hw";
		reg = <0xac53000 0x4000>;
		reg-cam-base = <0x53000>;
		interrupt-names = "jpeg";
		interrupts = <GIC_SPI 474 IRQ_TYPE_EDGE_RISING>;
		regulator-names = "camss-vdd";
		camss-vdd-supply = <&titan_top_gdsc>;
		clock-names =
			"jpegenc_clk_src",
			"jpegenc_clk";
		clocks =
			<&clock_camcc CAM_CC_JPEG_CLK_SRC>,
			<&clock_camcc CAM_CC_JPEG_CLK>;

		clock-rates = <600000000 0>;
		src-clock-name = "jpegenc_clk_src";
		clock-cntl-level = "nominal";
		status = "ok";
	};

	cam_jpeg_dma: qcom,jpegdma@ac57000 {
		cell-index = <0>;
		compatible = "qcom,cam_jpeg_dma";
		reg-names = "jpegdma_hw";
		reg = <0xac57000 0x4000>;
		reg-cam-base = <0x57000>;
		interrupt-names = "jpegdma";
		interrupts = <GIC_SPI 475 IRQ_TYPE_EDGE_RISING>;
		regulator-names = "camss-vdd";
		camss-vdd-supply = <&titan_top_gdsc>;
		clock-names =
			"jpegdma_clk_src",
			"jpegdma_clk";
		clocks =
			<&clock_camcc CAM_CC_JPEG_CLK_SRC>,
			<&clock_camcc CAM_CC_JPEG_CLK>;

		clock-rates = <600000000 0>;
		src-clock-name = "jpegdma_clk_src";
		clock-cntl-level = "nominal";
		status = "ok";
	};

	qcom,cam-fd {
		compatible = "qcom,cam-fd";
		compat-hw-name = "qcom,fd";
		num-fd = <1>;
		status = "ok";
	};

	cam_fd: qcom,fd@ac5f000 {
		cell-index = <0>;
		compatible = "qcom,fd600";
		reg-names = "fd_core", "fd_wrapper";
		reg = <0xac5f000 0x1000>,
			<0xac60000 0x400>;
		reg-cam-base = <0x5f000 0x60000>;
		interrupt-names = "fd";
		interrupts = <GIC_SPI 462 IRQ_TYPE_EDGE_RISING>;
		regulator-names = "camss-vdd";
		camss-vdd-supply = <&titan_top_gdsc>;
		clock-names =
			"fd_core_clk_src",
			"fd_core_clk",
			"fd_core_uar_clk";
		clocks =
			<&clock_camcc CAM_CC_FD_CORE_CLK_SRC>,
			<&clock_camcc CAM_CC_FD_CORE_CLK>,
			<&clock_camcc CAM_CC_FD_CORE_UAR_CLK>;
		src-clock-name = "fd_core_clk_src";
		clock-control-debugfs = "true";
		clock-cntl-level = "svs", "svs_l1", "turbo";
		clock-rates =
			<400000000 0 0>,
			<480000000 0 0>,
			<600000000 0 0>;
		status = "ok";
	};
};
